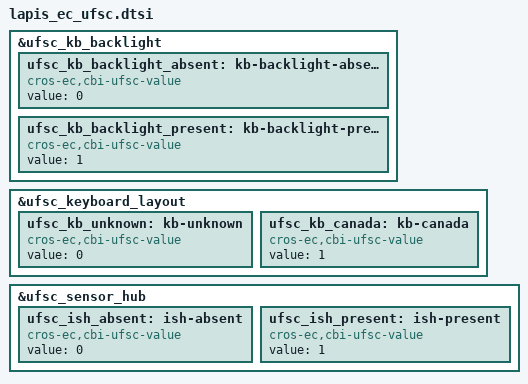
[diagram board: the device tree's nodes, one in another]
/* Auto-generated by generate_ufsc.py */

&ufsc_kb_backlight {
	ufsc_kb_backlight_absent: kb-backlight-absent {
		compatible = "cros-ec,cbi-ufsc-value";
		status = "okay";
		value = <0>;
	};
	ufsc_kb_backlight_present: kb-backlight-present {
		compatible = "cros-ec,cbi-ufsc-value";
		status = "okay";
		value = <1>;
	};
};

&ufsc_keyboard_layout {
	ufsc_kb_unknown: kb-unknown {
		compatible = "cros-ec,cbi-ufsc-value";
		status = "okay";
		value = <0>;
	};
	ufsc_kb_canada: kb-canada {
		compatible = "cros-ec,cbi-ufsc-value";
		status = "okay";
		value = <1>;
	};
};

&ufsc_sensor_hub {
	ufsc_ish_absent: ish-absent {
		compatible = "cros-ec,cbi-ufsc-value";
		status = "okay";
		value = <0>;
	};
	ufsc_ish_present: ish-present {
		compatible = "cros-ec,cbi-ufsc-value";
		status = "okay";
		value = <1>;
	};
};

